# ISS_IPIPEIF register map
Vendor: Texas Instruments
Peripheral module from a debugger description file (folder omap5430_ES2_PUBLIC).
Registers are 32-bit, access per field, reset 0x0 unless marked. A register's access mark holds for its fields unless they carry their own. Offsets are as the file gives them; lines under a group give offsets from that group; [hi:lo] are bit positions; {n}, {i} and the like mark numbered series; 'fields as' and 'values as' point back to an identical list; <NAME> marks a mode.

## ISS_IPIPEIF
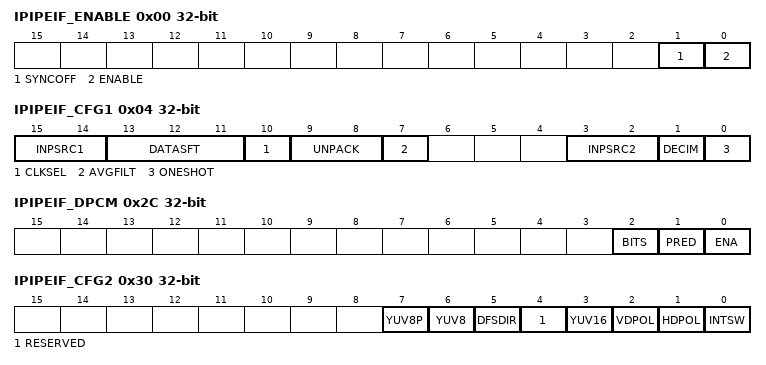
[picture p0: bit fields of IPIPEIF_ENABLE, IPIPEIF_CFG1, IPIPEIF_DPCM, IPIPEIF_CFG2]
0x00 IPIPEIF_ENABLE
  [1] SYNCOFF rw — VD output mask This register masks the VD output to the IPIPE module. This can be useful when one wants to read data from SDRAM which are stored in a double buffer. If the VD is not masked each time we start the module an new VD will be generated to the IPIPEIF module. Let's consider two buffers A and B of N lines each. *This bit field is latched by VD.
    0=newEnum1 (VD output mask is disabled.); 1=newEnum2 (VD output mask is enabled.)
  [0] ENABLE rw — IPIPE I/F Enable This register is used to start the operation of SDRAM buffer memory read and generates SYNC signals. This register is available when INPSRC1 or INPSCR2 = 1, 2 or 3.
    0=newEnum1 (disable); 1=newEnum2 (enable)
0x04 IPIPEIF_CFG1 — IPIPEIF Configuration #1
  [15:14] INPSRC1 rw — Selects the source for the mux (VPORT / ISIF / SDRAM) as well as the data format type.
    0=newEnum1 (VPORT_RAW); 1=newEnum2 (SDRAM_RAW); 3=newEnum4 (SDRAM_YUV); 2=newEnum3 (ISIF_DARKFM Input ports to DFS submodule are VPORT and SDRAM.)
  [13:11] DATASFT rw — SDRAM read data shift This register is available when INPSRC1 or INPSRC2 = 1 or 2, that is, when data are read from SDRAM.
    6=newEnum1 (Output data[11:0] = (read data[15:4] >> 4) & 0x0FFF); {v}=newEnum{v+1} (Output data[11:0] = (read data[11:0] << {v}) & 0x0FFF) (v=1..4); 7=newEnum8 (Output data[11:0] = (read data[15:4] >>4) & 0x0FFF); 0=newEnum8 (Output data[11:0] = (read data[11:0]) & 0x0FFF); 5=newEnum6 (Output data[11:0] = (read data[15:4] >> 4) & 0x0FFF)
  [10] CLKSEL rw — IPIPEIF and IPIPE module pixel clock selection. This register must be set to 1 when INPSRC1 or INPSRC2 = 1 or 3, that is, data are solely read from SDRAM (VPORT inactive).
    0=newEnum1 (Selects the pixel clock from the VPORT.); 1=newEnum2 (Selects the pixel clock from the fractional clock divider. The fractional clock divider value is setup with the register.)
  [9:8] UNPACK rw — 8-Bit, 12-bit Packed Mode When sensor raw data are stored in 8-bit packed mode or 12-bit packed mode, this register should code 1 or 3. This register is effective when INPSRC = 1 or 2.
    0=newEnum1 (16 bits / pixel); 1=newEnum2 (8 bits / pixel); 3=newEnum4 (12 bits / pixel); 2=newEnum3 (8 bits / pixel + inverse A law (8 bits to 10 bits))
  [7] AVGFILT rw — Averaging Filter It applies (1,2,1) filter for the RGB/YCbCr data. *This bit field is latched by VD.
    0=newEnum1 (disable); 1=newEnum2 (enable)
  [3:2] INPSRC2 rw — Selects the source for the mux (ISIF / SDRAM) as well as the data format type.
    0=newEnum1 (ISIF); 1=newEnum2 (SDRAM_RAW); 3=newEnum4 (SDRAM_YUV); 2=newEnum3 (ISIF_DARKFM Input ports to DFS submodule are ISIF and SDRAM.)
  [1] DECIM rw — Pixel Decimation The decimation rate defined by RSZ register. *This bit field is latched by VD.
    0=newEnum2 (No decimation); 1=newEnum2 (Decimation)
  [0] ONESHOT rw — One Shot Mode This register is available when INPSRC = 1 or 3.
    0=newEnum1 (Continuous mode); 1=newEnum2 (One shot mode)
0x08 IPIPEIF_PPLN — IPIPEIF Interval of HD / Start pixel in HD
  [12:0] PPLN rw — Case-1: Interval of Horizontal Sync (HD) Specifies the interval of horizontal sync. This register is available when INPSRC = 1 or 3. Case-2: Start Pixel in Horizontal Sync (HD) Specifies the start pixel in horizontal sync. This register is available when INPSRC = 2 *This bit field is latched by VD.
0x0C IPIPEIF_LPFR — IPIPEIF Interval of VD / Start line in VD
  [12:0] LPFR rw — Case-1: Interval of Vertical Sync (VD) Specifies the interval of vertical sync. This register is available when INPSRC = 1 or 3. Case-2: Start Pixel in Vertical Sync (VD) Specifies the start line in vertical sync. This register is available when INPSRC = 2 *This bit field is latched by VD.
0x10 IPIPEIF_HNUM — IPIPEIF Number of valid pixels per line
  [12:0] HNUM rw — The Number of Valid Pixels in a Line Specifies the number of valid pixels in a horizontal line. This register is available when INPSRC = 1, 2 or 3 *This bit field is latched by VD.
0x14 IPIPEIF_VNUM — IPIPEIF Number of valid lines per frame
  [12:0] VNUM rw — The Number of Valid Line in a Vertical Specifies the number of valid line in a vertical. This register is available when INPSRC = 1, 2 or 3 *This bit field is latched by VD.
0x18 IPIPEIF_ADDRU — IPIPEIF Memory Address (Upper)
  [10:0] ADDRU rw — Memory Address - Upper Memory address upper 11-bits are specified in units of 32-bytes This register is available when INPSRC = 1, 2 or 3. *This bit field is latched by VD.
0x1C IPIPEIF_ADDRL — IPIPEIF Memory Address (Lower)
  [15:0] ADDRL rw — Memory Address - Lower Memory address lower 16-bits are specified in units of 32-bytes. This register is available when INPSRC = 1, 2 or 3. *This bit field is latched by VD.
0x20 IPIPEIF_ADOFS — IPIPEIF Address offset
  [11:0] ADOFS rw — Specifies the SDRAM stride for each line in units of 32-bytes. This register is available when reading data from SDRAM: INPSRC1 or INPSRC2 = 1, 2 or 3. Assuming that the first line is at position ADDR, the second line is at address ADDR+ ADOFS, etc. *This bit field is latched by VD.
0x24 IPIPEIF_RSZ reset 0x10 — IPIPEIF Horizontal Resizing Parameter on IPIPE data path
  [6:0] RSZ rw — Horizontal Resizing Parameter for IPIPE data path Specifies the horizontal resizing parameter. The RSZ register can be configured within 16 to 112 range. This resizing ratio is determined by 16/RSZ (= 1/1 to 1/7) *This bit field is latched by VD.
0x28 IPIPEIF_GAIN reset 0x200 — IPIPEIF Gain Parameter
  [9:0] GAIN rw — Gain Parameter Specifies the gain applied to RAW data before it is forwarded to the IPIPE module. The gain value is expressed using the U10Q9 fractional format. The range is from 0.00195 (1/512) to 1.99805(1023/512). By default the unity gain is applied, that is, IPIPEIF_GAIN.GAIN = 0x200. The gain is applied to RAW data only (IPIPEIF_CFG1.INPSRC2 != 3): the gain is not applied if the input data is YCbCr. *This bit field is latched by VD.
0x2C IPIPEIF_DPCM — IPIPEIF DPCM configuration This register applies only if .UNPACK = 1, that is, RAW8 data is read from SDRAM.
  [2] BITS rw — DPCM bit mode for SDRAM data
    0=newEnum1 (8bit to 10bit DPCM decompression); 1=newEnum2 (8bit to 12bit DPCM decompression)
  [1] PRED rw — DPCM prediction mode for SDRAM data
    0=newEnum1 (Simple predictor); 1=newEnum2 (Advanced predictor)
  [0] ENA rw — DPCM decompression enable for SDRAM data.
    0=newEnum1 (DPCM off (no decompression)); 1=newEnum2 (DPCM on)
0x30 IPIPEIF_CFG2 — IPIPEIF Configuration #2
  [7] YUV8P rw — 8-bit YUV data unpacking to 16 bits When IPIPEIF_CFG1.INPSRC2 = 0 and IPIPEIF_CFG2.YUV16 = 1, the 8-bit YUV data are transformed into 16-bit YUV data. The way the data are unpacked from 8 bits to 16 bits is controlled by the IPIPEIF_CFG2.YUV8P register. The upper 8 bits of the 16-bit output are set to 0.
    0=newEnum1 (Y output on even pixels C output on odd pixels); 1=newEnum2 (C output on even pixels Y output on odd pixels)
  [6] YUV8 rw — YUV 8bit mode When ISIF_CFG1.INPSRC2 = 0 and YUV16 = 1, setting this bit to 1 enables the conversion from 8-bit YUV input to 16-bit YUV. This register is used when the input data from the ISIF module is 8-bit YUV data.
    0=newEnum1 (YUV16); 1=newEnum2 (YUV8 to 16)
  [5] DFSDIR rw — DFS direction Selects the direction of dark frame subtraction.
    0=newEnum1 (VPORT IF(capture frame) - SDRAM (dark frame)); 1=newEnum2 (SDRAM (capture frame) - VPORT IF(dark frame))
  [4] RESERVED rw — Read returns reset value
  [3] YUV16 rw — Data type selection. The behavior of this bit field depends upon other register settings. The functionality is best explained with the following pseudo code: if ((CFG1.INPSRC2==0 &amp;&amp; CFG2.YUV16) || CFG1.INPSRC2==3) { data_out[15:0] = yuv[15:0] } else if (CFG1.INPSRC2==1 &amp;&amp; CFG2.YUV16 &amp;&amp; CFG1.UNPACK=1) { data_out[15:8] = gain_clip[7:0]; data_out[ 7:0] = 0; } else { data_out[15:12] = 0; data_out[11: 0] = gain_clip[11:0]; } where: o data_out[15:0] = 16-bit YUV or 12-bit RAW data to ipipe o yuv[15:0] = 16-bit YUV data from 'horizontal pixel decimator' block. o gain_clip[11:0] = 12-bit RAW data from 'gain' block.
    0=newEnum1 (12-bit RAW data); 1=newEnum2 (16-bit YUV data)
  [2] VDPOL rw — VD Sync Polarity When input VD is active low SYNC pulse, this bit needs to be set to 1.
    0=newEnum1 (Positive); 1=newEnum2 (Negative)
  [1] HDPOL rw — HD Sync Polarity When input HD is active low SYNC pulse, this bit needs to be set to 1.
    0=newEnum1 (Positive); 1=newEnum2 (Negative)
  [0] INTSW rw — IPIPEIF interrupt source selection. This register select the interrupt source.
    0=newEnum1 (Start position of VD from VPORT interface); 1=newEnum2 (Start position of VD from ISIF module)
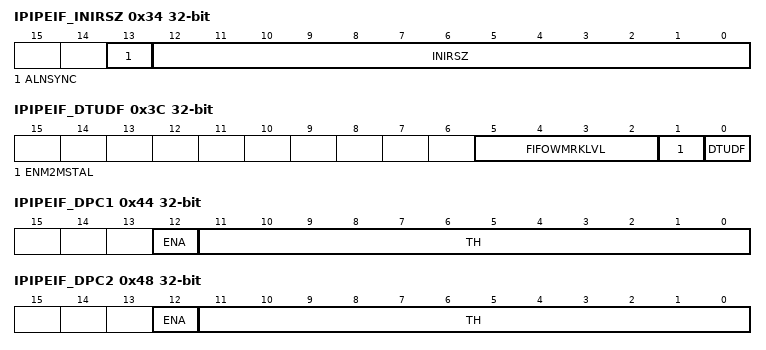
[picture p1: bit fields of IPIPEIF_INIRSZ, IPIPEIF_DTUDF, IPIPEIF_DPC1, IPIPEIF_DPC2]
0x34 IPIPEIF_INIRSZ — IPIPEIF resize initial position - IPIPE data path.
  [13] ALNSYNC rw — Align the HSYNC, VSYNC to initial position defined by INIRSZ.
    0=newEnum1 (Disable); 1=newEnum2 (Enable)
  [12:0] INIRSZ rw — Offset used to re-initialize the HD/VD position after resizer. From 0 to 8191 PCLK cycles. Skips INIRSZ pixels for every line.
0x38 IPIPEIF_OCLIP reset 0xFFF — IPIPEIF output clipping value
  [11:0] OCLIP rw — Output clipping value after gain control on IPIPE data path. This value is in U12Q0 data format.
0x3C IPIPEIF_DTUDF — IPIPEIF data underflow detection
  [5:2] FIFOWMRKLVL rw — To guarantee that the FIFO does not overflow, the stall request is deasserted only when a certain number of locations in the FIFO are free. The number of free locations is configurable. A safe number of mandatory free locations can be configured by taking into consideration the pixel clock frequency (PCLK) with respect to that of the functional clock (ISP_FCLK). The worst case occurs when PCLK = ISP_FCLK. In that case, value should be configured to 0 (i.e. 16 free locations), so that the stall will be deasserted only when the 16-deep FIFO is completely empty. 0: Stall deassertion when FIFO is empty (16 free locations) and SDRAM data available; 1: Stall deassertion when FIFO has not more than 1 valid entry and SDRAM data available; … 15: Stall deassertion when FIFO has not more than 15 valid entries and SDRAM data available;
  [1] ENM2MSTAL rw — Enable memory-to-memory stall mechanism: 0: disable (no special stall mechanism for memory-to-memory use cases); 1: enable (stall mechanism for memory-to-memory use cases);
  [0] DTUDF rw — Data under flow error status register. Reading 1 shows there is data under flow and at least one data is corrupted while reading from SDRAM. Writing 1 to this register clears (=0) the error (=1) status. Underflow errors are non recoverable at ISP level, need to do a soft reset at ISS level. The IPIPEIF_UDF interrupt is generated when an underflow happens. The interrupt avoids polling this register for errors. If bit [1] ENM2MSTAL = 1, then programmers need to ensure that the SW does not clear bit [0] DTUDF, as this would reset the MTC read interface. Bit DTUDF can be cleared only in the on-the-fly operation where the stall mechanism will not work.
0x40 IPIPEIF_CLKDIV reset 0x1 — IPIPEIF CLOCK DIVIDER
  [15:0] CLKDIV rw — IPIPEIF clock rate configuration IPIPE/IPIPEIF clock frequency = M/N x ISP_FCLK clock frequency. We have M = CLKDIV[15:8] + 1 and N = CLKDIV[7:0] + 1 This register is available when IPIPEIF_CFG1.CLKSEL = 1.
0x44 IPIPEIF_DPC1 — IPIPEIF defect pixel correction #1
  [12] ENA rw — DPC enable. Applies DPC for video port data, ISIF input path.
    0=newEnum1 (Disable); 1=newEnum2 (Enable)
  [11:0] TH rw — DPC threshold value
0x48 IPIPEIF_DPC2 — IPIPEIF defect pixel correction #2
  [12] ENA rw — DPC enable. Applies DPC for SDRAM input path.
    0=newEnum1 (Disable); 1=newEnum2 (Enable)
  [11:0] TH rw — DPC threshold value
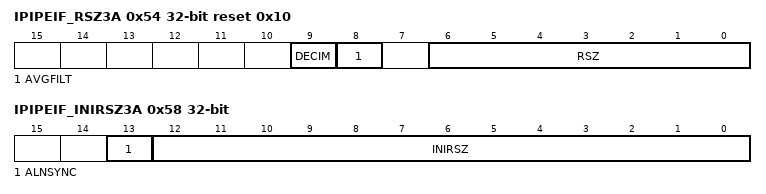
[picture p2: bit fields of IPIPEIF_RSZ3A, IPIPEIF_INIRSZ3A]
0x54 IPIPEIF_RSZ3A reset 0x10 — IPIPEIF HORIZONTAL RESIZING PARAMETER FOR H3A
  [9] DECIM rw — Pixel Decimation Enable The decimation rate defined by the RSZ bit field. *This bit field is latched by VD.
    0=newEnum1 (No Decimation); 1=newEnum2 (Decimate)
  [8] AVGFILT rw — Averaging Filter It applies a (1, 2, 1) filter for the RGB/YCbCr data. *This bit field is latched by VD.
    0=newEnum1 (Disable); 1=newEnum2 (Enable)
  [6:0] RSZ rw — Horizontal Resizing Parameter for H3A data path Specifies the horizontal resizing parameter. The RSZ register can be configured within 16 to 112 range. This resizing ratio is determined by 16/RSZ (= 1/1 to 1/7) *This bit field is latched by VD.
0x58 IPIPEIF_INIRSZ3A — IPIPEIF resize initial position - H3A data path.
  [13] ALNSYNC rw — Align the HD, VD to initial position defined by the INIRSZ bit field. It means that HD and VD are effectively shifted by INIRSZ pixel clock cycles.
    0=newEnum1 (Disable); 1=newEnum2 (Enable)
  [12:0] INIRSZ rw — Offset used to re-initialize the HD/VD position after resizer. From 0 to 8191 PCLK cycles. Skips INIRSZ pixels for every line.
